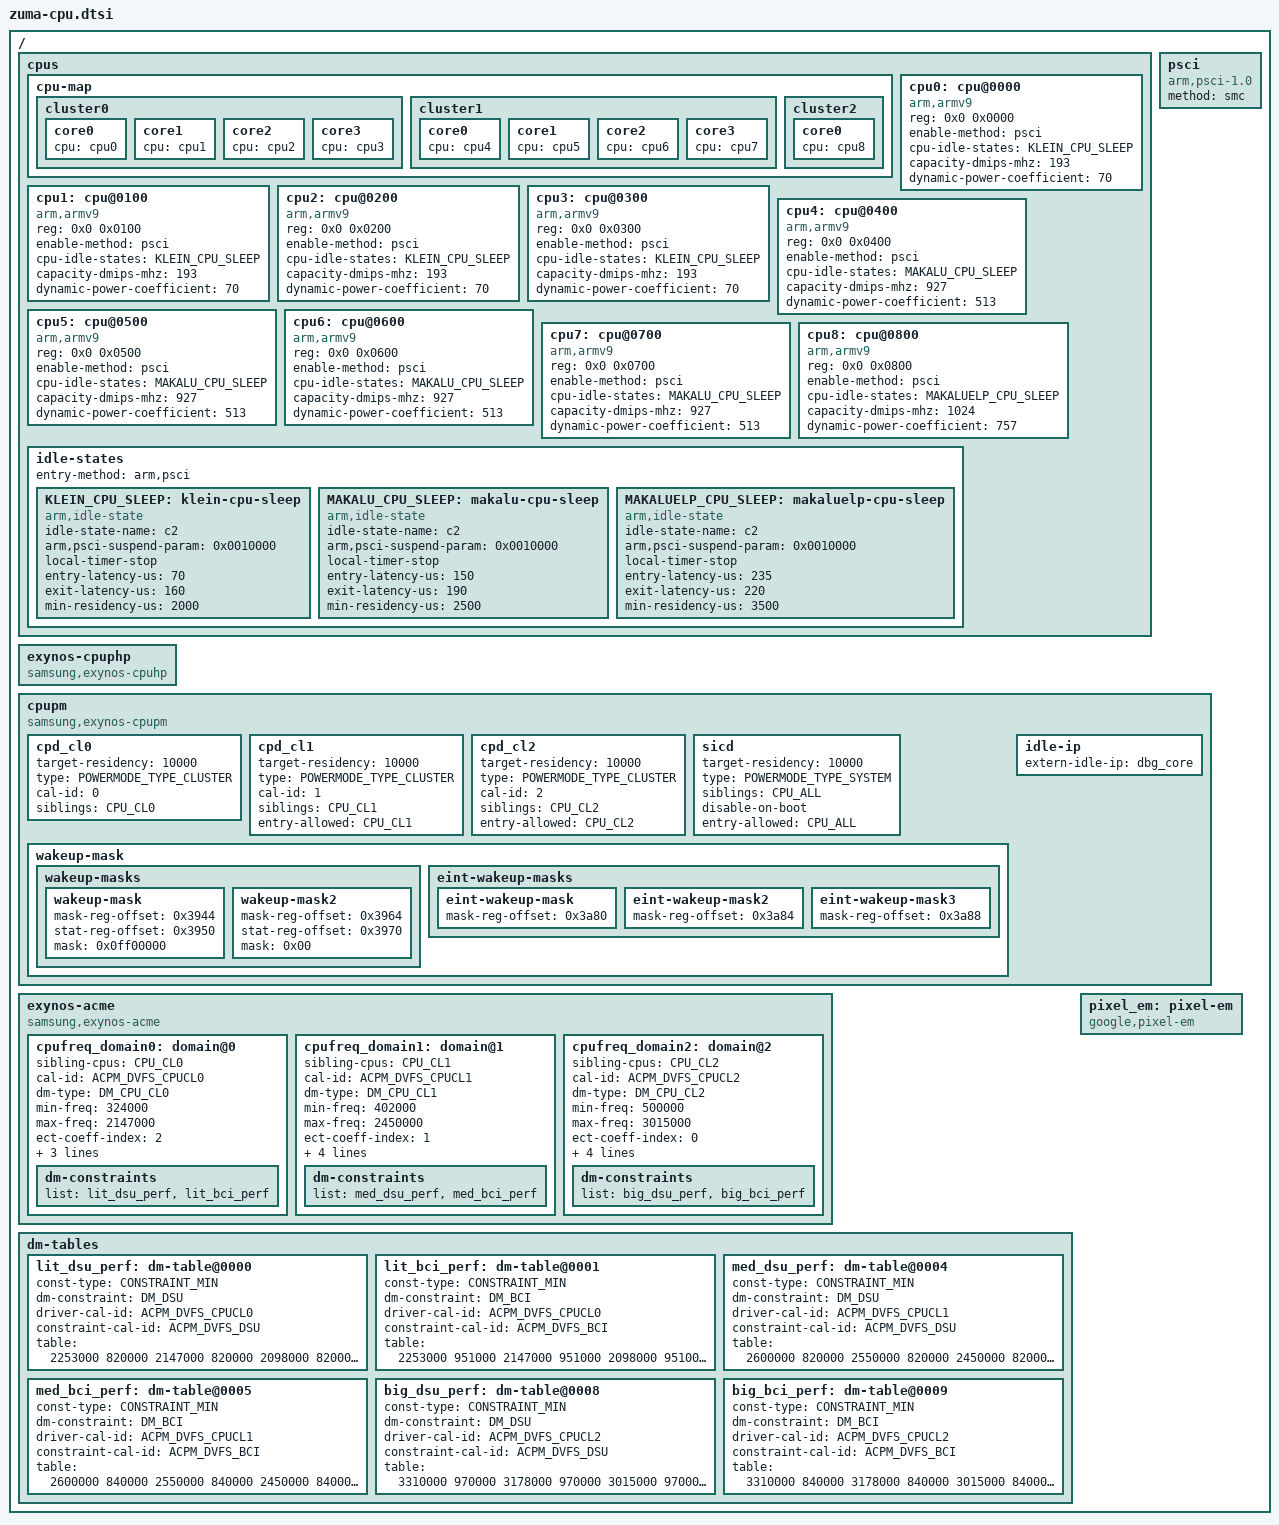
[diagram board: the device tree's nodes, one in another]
// SPDX-License-Identifier: GPL-2.0-only
/*
 * Copyright 2022 Google LLC.
 *
 */

/ {
	cpus {
		#address-cells = <2>;
		#size-cells = <0>;

		#define CPU_CL0 "0-3"
		#define CPU_CL1 "4-7"
		#define CPU_CL2 "8"
		#define CPU_ALL "0-8"

		cpu-map {
			cluster0 {
				core0 {
					cpu = <&cpu0>;
				};
				core1 {
					cpu = <&cpu1>;
				};
				core2 {
					cpu = <&cpu2>;
				};
				core3 {
					cpu = <&cpu3>;
				};
			};
			cluster1 {
				core0 {
					cpu = <&cpu4>;
				};
				core1 {
					cpu = <&cpu5>;
				};
				core2 {
					cpu = <&cpu6>;
				};
				core3 {
					cpu = <&cpu7>;
				};
			};
			cluster2 {
				core0 {
					cpu = <&cpu8>;
				};
			};
		};

		cpu0: cpu@0000 {
			device_type = "cpu";
			compatible = "arm,armv9";
			reg = <0x0 0x0000>;
			enable-method = "psci";
			cpu-idle-states =  <&KLEIN_CPU_SLEEP>;
			capacity-dmips-mhz = <193>;
			dynamic-power-coefficient = <70>;
		};
		cpu1: cpu@0100 {
			device_type = "cpu";
			compatible = "arm,armv9";
			reg = <0x0 0x0100>;
			enable-method = "psci";
			cpu-idle-states =  <&KLEIN_CPU_SLEEP>;
			capacity-dmips-mhz = <193>;
			dynamic-power-coefficient = <70>;
		};
		cpu2: cpu@0200 {
			device_type = "cpu";
			compatible = "arm,armv9";
			reg = <0x0 0x0200>;
			enable-method = "psci";
			cpu-idle-states =  <&KLEIN_CPU_SLEEP>;
			capacity-dmips-mhz = <193>;
			dynamic-power-coefficient = <70>;
		};
		cpu3: cpu@0300 {
			device_type = "cpu";
			compatible = "arm,armv9";
			reg = <0x0 0x0300>;
			enable-method = "psci";
			cpu-idle-states =  <&KLEIN_CPU_SLEEP>;
			capacity-dmips-mhz = <193>;
			dynamic-power-coefficient = <70>;
		};
		cpu4: cpu@0400 {
			device_type = "cpu";
			compatible = "arm,armv9";
			reg = <0x0 0x0400>;
			enable-method = "psci";
			cpu-idle-states =  <&MAKALU_CPU_SLEEP>;
			capacity-dmips-mhz = <927>;
			dynamic-power-coefficient = <513>;
		};
		cpu5: cpu@0500 {
			device_type = "cpu";
			compatible = "arm,armv9";
			reg = <0x0 0x0500>;
			enable-method = "psci";
			cpu-idle-states =  <&MAKALU_CPU_SLEEP>;
			capacity-dmips-mhz = <927>;
			dynamic-power-coefficient = <513>;
		};
		cpu6: cpu@0600 {
			device_type = "cpu";
			compatible = "arm,armv9";
			reg = <0x0 0x0600>;
			enable-method = "psci";
			cpu-idle-states =  <&MAKALU_CPU_SLEEP>;
			capacity-dmips-mhz = <927>;
			dynamic-power-coefficient = <513>;
		};
		cpu7: cpu@0700 {
			device_type = "cpu";
			compatible = "arm,armv9";
			reg = <0x0 0x0700>;
			enable-method = "psci";
			cpu-idle-states =  <&MAKALU_CPU_SLEEP>;
			capacity-dmips-mhz = <927>;
			dynamic-power-coefficient = <513>;
		};
		cpu8: cpu@0800 {
			device_type = "cpu";
			compatible = "arm,armv9";
			reg = <0x0 0x0800>;
			enable-method = "psci";
			cpu-idle-states =  <&MAKALUELP_CPU_SLEEP>;
			capacity-dmips-mhz = <1024>;
			dynamic-power-coefficient = <757>;
		};

		idle-states {
			entry-method = "arm,psci";
			KLEIN_CPU_SLEEP: klein-cpu-sleep {
				idle-state-name = "c2";
				compatible = "arm,idle-state";
				arm,psci-suspend-param = <0x0010000>;
				local-timer-stop;
				entry-latency-us = <70>;
				exit-latency-us = <160>;
				min-residency-us = <2000>;
				status = "okay";
			};
			MAKALU_CPU_SLEEP: makalu-cpu-sleep {
				idle-state-name = "c2";
				compatible = "arm,idle-state";
				arm,psci-suspend-param = <0x0010000>;
				local-timer-stop;
				entry-latency-us = <150>;
				exit-latency-us = <190>;
				min-residency-us = <2500>;
				status = "okay";
			};
			MAKALUELP_CPU_SLEEP: makaluelp-cpu-sleep {
				idle-state-name = "c2";
				compatible = "arm,idle-state";
				arm,psci-suspend-param = <0x0010000>;
				local-timer-stop;
				entry-latency-us = <235>;
				exit-latency-us = <220>;
				min-residency-us = <3500>;
				status = "okay";
			};
		};
	};

	psci {
		compatible = "arm,psci-1.0";
		method = "smc";
		status = "okay";
	};

        exynos-cpuphp {
                compatible = "samsung,exynos-cpuhp";
                status = "okay";
        };

	cpupm {
		#define POWERMODE_TYPE_CLUSTER  0
		#define POWERMODE_TYPE_SYSTEM   1

		compatible = "samsung,exynos-cpupm";
		status = "okay";

		cpd_cl0 {
			device_type = "cpupm";
			target-residency = <10000>;
			type = <POWERMODE_TYPE_CLUSTER>;
			cal-id = <0>;
			siblings = CPU_CL0;
		};

		cpd_cl1 {
			device_type = "cpupm";
			target-residency = <10000>;
			type = <POWERMODE_TYPE_CLUSTER>;
			cal-id = <1>;
			siblings = CPU_CL1;
			entry-allowed = CPU_CL1;
		};

		cpd_cl2 {
			device_type = "cpupm";
			target-residency = <10000>;
			type = <POWERMODE_TYPE_CLUSTER>;
			cal-id = <2>;
			siblings = CPU_CL2;
			entry-allowed = CPU_CL2;
		};

		sicd {
			device_type = "cpupm";
			target-residency = <10000>;
			type = <POWERMODE_TYPE_SYSTEM>;
			siblings = CPU_ALL;
			disable-on-boot;
			entry-allowed = CPU_ALL;
		};

		wakeup-mask {
			wakeup-masks {
				wakeup-mask {
					mask-reg-offset = <0x3944>;
					stat-reg-offset = <0x3950>;
					mask = <0x0ff00000>;
				};
				wakeup-mask2 {
					mask-reg-offset = <0x3964>;
					stat-reg-offset = <0x3970>;
					mask = <0x00>;
				};
			};

			eint-wakeup-masks {
				eint-wakeup-mask {
					mask-reg-offset = <0x3a80>;
				};
				eint-wakeup-mask2 {
					mask-reg-offset = <0x3a84>;
				};
				eint-wakeup-mask3 {
					mask-reg-offset = <0x3a88>;
				};
			};
		};

		idle-ip {
			extern-idle-ip =
				"dbg_core";
		};
	};

	exynos-acme {
		compatible = "samsung,exynos-acme";
		status = "okay";

		cpufreq_domain0: domain@0 {
			sibling-cpus = CPU_CL0;
			cal-id = <ACPM_DVFS_CPUCL0>;
			dm-type = <DM_CPU_CL0>;

			min-freq = <324000>;
			max-freq = <2147000>;

			#cooling-cells = <2>; /* min followed by max */
			ect-coeff-index = <2>;
			tz-cooling-name = "LITTLE";
			skip-boot-pmqos;
			use-em-coeff;

			dm-constraints {
			  list = <&lit_dsu_perf &lit_bci_perf>;
			};
		};

		cpufreq_domain1: domain@1 {
			sibling-cpus = CPU_CL1;
			cal-id = <ACPM_DVFS_CPUCL1>;
			dm-type = <DM_CPU_CL1>;

			min-freq = <402000>;
			max-freq = <2450000>;

			#cooling-cells = <2>; /* min followed by max */
			ect-coeff-index = <1>;
			tz-cooling-name = "MID";
			skip-boot-pmqos;
			use-em-coeff;
			need-awake;

			dm-constraints {
                          list = <&med_dsu_perf &med_bci_perf>;
                        };
		};

		cpufreq_domain2: domain@2 {
			sibling-cpus = CPU_CL2;
			cal-id = <ACPM_DVFS_CPUCL2>;
			dm-type = <DM_CPU_CL2>;

			min-freq = <500000>;
			max-freq = <3015000>;

			#cooling-cells = <2>; /* min followed by max */
			ect-coeff-index = <0>;
			tz-cooling-name = "BIG";
			skip-boot-pmqos;
			use-em-coeff;
			need-awake;

			dm-constraints {
                          list = <&big_dsu_perf &big_bci_perf>;
                        };
		};
	};

	dm-tables {
		lit_dsu_perf: dm-table@0000 {
			const-type = <CONSTRAINT_MIN>;
			dm-constraint = <DM_DSU>;
			driver-cal-id = <ACPM_DVFS_CPUCL0>;
			constraint-cal-id = <ACPM_DVFS_DSU>;

				/* CL0          DSU */
			table = < 2253000       820000
				2147000       820000
				2098000       820000
				2024000       820000
				1950000       820000
				1844000       820000
				1704000       820000
				1548000       820000
				1475000       820000
				1328000       820000
				1197000       820000
				1098000       610000
				975000        610000
				820000        324000
				615000        324000
				324000        324000 >;
		};
		lit_bci_perf: dm-table@0001 {
			const-type = <CONSTRAINT_MIN>;
			dm-constraint = <DM_BCI>;
			driver-cal-id = <ACPM_DVFS_CPUCL0>;
			constraint-cal-id = <ACPM_DVFS_BCI>;

				/* CL0          BCI */
			table = < 2253000       951000
				2147000       951000
				2098000       951000
				2024000       951000
				1950000       951000
				1844000       951000
				1704000       951000
				1548000       840000
				1475000       840000
				1328000       840000
				1197000       840000
				1098000       840000
				975000        575000
				820000        575000
				615000        575000
				324000        315000 >;
		};
		med_dsu_perf: dm-table@0004 {
			const-type = <CONSTRAINT_MIN>;
			dm-constraint = <DM_DSU>;
			driver-cal-id = <ACPM_DVFS_CPUCL1>;
			constraint-cal-id = <ACPM_DVFS_DSU>;

				/* CL1          DSU */
			table = < 2600000     820000
				2550000       820000
				2450000       820000
				2352000       820000
				2245000       820000
				2130000       820000
				1999000       820000
				1836000       820000
				1622000       820000
				1549000       820000
				1418000       610000
				1328000       610000
				1221000       610000
				1082000       610000
				910000        610000
				721000        610000
				697000        610000
				578000        610000
				402000        324000 >;
		};
		med_bci_perf: dm-table@0005 {
			const-type = <CONSTRAINT_MIN>;
			dm-constraint = <DM_BCI>;
			driver-cal-id = <ACPM_DVFS_CPUCL1>;
			constraint-cal-id = <ACPM_DVFS_BCI>;

				/* CL1          BCI */
			table = < 2600000     840000
				2550000       840000
				2450000       840000
				2352000       840000
				2245000       840000
				2130000       840000
				1999000       840000
				1836000       840000
				1622000       840000
				1549000       840000
				1418000       575000
				1328000       575000
				1221000       575000
				1082000       575000
				910000        575000
				721000        575000
				697000        575000
				578000        575000
				402000        315000 >;
		};
		big_dsu_perf: dm-table@0008 {
			const-type = <CONSTRAINT_MIN>;
			dm-constraint = <DM_DSU>;
			driver-cal-id = <ACPM_DVFS_CPUCL2>;
			constraint-cal-id = <ACPM_DVFS_DSU>;

				/* CL2          DSU */
			table = < 3310000     970000
				3178000       970000
				3015000       970000
				2914000       970000
				2802000       970000
				2687000       970000
				2556000       970000
				2409000       970000
				2294000       970000
				2147000       970000
				2049000       970000
				1901000       970000
				1852000       970000
				1745000       970000
				1557000       970000
				1328000       820000
				1164000       610000
				893000        610000
				500000        324000 >;
		};
		big_bci_perf: dm-table@0009 {
			const-type = <CONSTRAINT_MIN>;
			dm-constraint = <DM_BCI>;
			driver-cal-id = <ACPM_DVFS_CPUCL2>;
			constraint-cal-id = <ACPM_DVFS_BCI>;

				/* CL2          BCI */
			table = < 3310000     840000
				3178000       840000
				3015000       840000
				2914000       840000
				2802000       840000
				2687000       840000
				2556000       840000
				2409000       840000
				2294000       840000
				2147000       840000
				2049000       840000
				1901000       840000
				1852000       840000
				1745000       840000
				1557000       840000
				1328000       575000
				1164000       575000
				893000        575000
				500000        315000 >;
		};
	};

	pixel_em: pixel-em {
		compatible = "google,pixel-em";
		// 'profiles' field defined in A0/B0 dtsi files
	};
};
